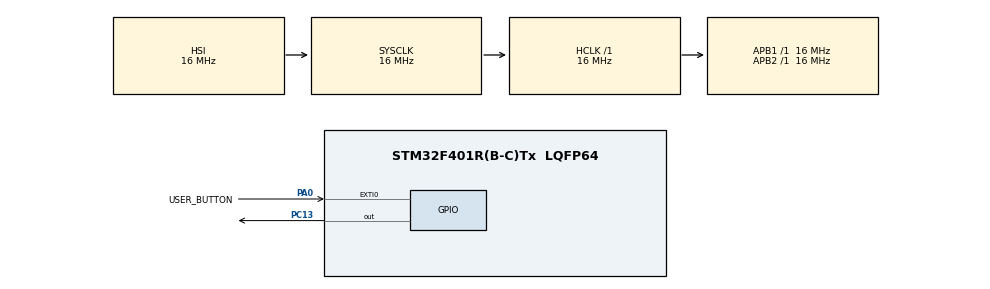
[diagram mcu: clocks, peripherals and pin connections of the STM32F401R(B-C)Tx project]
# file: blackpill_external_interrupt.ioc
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Mcu.Family=STM32F4
Mcu.Name=STM32F401R(B-C)Tx
Mcu.Package=LQFP64
NVIC.EXTI0_IRQn=true\:0\:0\:false\:false\:true\:true\:true\:true
NVIC.PriorityGroup=NVIC_PRIORITYGROUP_4
PA0-WKUP.GPIO_Label=USER_BUTTON
PA0-WKUP.GPIO_ModeDefaultEXTI=GPIO_MODE_IT_FALLING
PA0-WKUP.GPIO_PuPd=GPIO_PULLUP
PA0-WKUP.Signal=GPXTI0
PC13-ANTI_TAMP.PinState=GPIO_PIN_SET
PC13-ANTI_TAMP.Signal=GPIO_Output
ProjectManager.HeapSize=0x200
ProjectManager.StackSize=0x400
ProjectManager.TargetToolchain=STM32CubeIDE
RCC.AHBFreq_Value=16000000
RCC.APB1Freq_Value=16000000
RCC.APB2Freq_Value=16000000
RCC.CortexFreq_Value=16000000
RCC.HSE_VALUE=25000000
RCC.HSI_VALUE=16000000
RCC.LSE_VALUE=32768
RCC.SYSCLKFreq_VALUE=16000000
RCC.VCOOutputFreq_Value=192000000
board=custom

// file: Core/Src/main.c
/* USER CODE BEGIN Header */
/**
  ******************************************************************************
  * @file           : main.c
  * @brief          : Main program body
  ******************************************************************************
  * @attention
  *
  * Copyright (c) 2025 STMicroelectronics.
  * All rights reserved.
  *
  * This software is licensed under terms that can be found in the LICENSE file
  * in the root directory of this software component.
  * If no LICENSE file comes with this software, it is provided AS-IS.
  *
  ******************************************************************************
  */
/* USER CODE END Header */
#include "main.h"

void SystemClock_Config(void);
static void MX_GPIO_Init(void);

/* USER CODE BEGIN 0 */

uint8_t counter = 0; //Variable to select different toggling states

void HAL_GPIO_EXTI_Callback(uint16_t GPIO_Pin) //This function is called when an external interrupt occurs due to button press
{
	if(counter == 3) //Checking if max number of button presses have been reached and resetting if so
	{
		HAL_GPIO_WritePin(GPIOC, GPIO_PIN_13, 1); //It is essential to turn off the LED while resetting or else LED will stay on when the board resets while the LED was glowing in its previous state
		counter = 0; //Resetting the counter, LED will be OFF similar to when the board turns ON for the first time
	}
	else
	{
		++counter; //If max number of presses hasn't been reached, increment the counter
	}
}

/* USER CODE END 0 */

int main(void)
{

  /* MCU Configuration--------------------------------------------------------*/

  /* Reset of all peripherals, Initializes the Flash interface and the Systick. */
  HAL_Init();

  /* Configure the system clock */
  SystemClock_Config();

  /* Initialize all configured peripherals */
  MX_GPIO_Init();

  /* Infinite loop */
  while (1)
  {

    /* USER CODE BEGIN 3 */

	  if(counter == 1) //Toggling state 1 (fast switching)
	  {
		  HAL_GPIO_TogglePin(GPIOC, GPIO_PIN_13);
		  HAL_Delay(300);
	  }
	  else if(counter == 2) //Toggling state 2 (medium switching)
	  {
		  HAL_GPIO_TogglePin(GPIOC, GPIO_PIN_13);
		  HAL_Delay(900);
	  }
	  else if(counter == 3) //Toggling state 3 (slow switching)
	  {
		  HAL_GPIO_TogglePin(GPIOC, GPIO_PIN_13);
		  HAL_Delay(1500);
	  }

  }
  /* USER CODE END 3 */
}

void SystemClock_Config(void)
{
  RCC_OscInitTypeDef RCC_OscInitStruct = {0};
  RCC_ClkInitTypeDef RCC_ClkInitStruct = {0};

  /** Configure the main internal regulator output voltage
  */
  __HAL_RCC_PWR_CLK_ENABLE();
  __HAL_PWR_VOLTAGESCALING_CONFIG(PWR_REGULATOR_VOLTAGE_SCALE2);

  /** Initializes the RCC Oscillators according to the specified parameters
  * in the RCC_OscInitTypeDef structure.
  */
  RCC_OscInitStruct.OscillatorType = RCC_OSCILLATORTYPE_HSI;
  RCC_OscInitStruct.HSIState = RCC_HSI_ON;
  RCC_OscInitStruct.HSICalibrationValue = RCC_HSICALIBRATION_DEFAULT;
  RCC_OscInitStruct.PLL.PLLState = RCC_PLL_NONE;
  if (HAL_RCC_OscConfig(&RCC_OscInitStruct) != HAL_OK)
  {
    Error_Handler();
  }

  /** Initializes the CPU, AHB and APB buses clocks
  */
  RCC_ClkInitStruct.ClockType = RCC_CLOCKTYPE_HCLK|RCC_CLOCKTYPE_SYSCLK
                              |RCC_CLOCKTYPE_PCLK1|RCC_CLOCKTYPE_PCLK2;
  RCC_ClkInitStruct.SYSCLKSource = RCC_SYSCLKSOURCE_HSI;
  RCC_ClkInitStruct.AHBCLKDivider = RCC_SYSCLK_DIV1;
  RCC_ClkInitStruct.APB1CLKDivider = RCC_HCLK_DIV1;
  RCC_ClkInitStruct.APB2CLKDivider = RCC_HCLK_DIV1;

  if (HAL_RCC_ClockConfig(&RCC_ClkInitStruct, FLASH_LATENCY_0) != HAL_OK)
  {
    Error_Handler();
  }
}

static void MX_GPIO_Init(void)
{
  GPIO_InitTypeDef GPIO_InitStruct = {0};

  /* GPIO Ports Clock Enable */
  __HAL_RCC_GPIOC_CLK_ENABLE();
  __HAL_RCC_GPIOA_CLK_ENABLE();

  /*Configure GPIO pin Output Level */
  HAL_GPIO_WritePin(GPIOC, GPIO_PIN_13, GPIO_PIN_SET);

  /*Configure GPIO pin : PC13 */
  GPIO_InitStruct.Pin = GPIO_PIN_13;
  GPIO_InitStruct.Mode = GPIO_MODE_OUTPUT_PP;
  GPIO_InitStruct.Pull = GPIO_NOPULL;
  GPIO_InitStruct.Speed = GPIO_SPEED_FREQ_LOW;
  HAL_GPIO_Init(GPIOC, &GPIO_InitStruct);

  /*Configure GPIO pin : USER_BUTTON_Pin */
  GPIO_InitStruct.Pin = USER_BUTTON_Pin;
  GPIO_InitStruct.Mode = GPIO_MODE_IT_FALLING;
  GPIO_InitStruct.Pull = GPIO_PULLUP;
  HAL_GPIO_Init(USER_BUTTON_GPIO_Port, &GPIO_InitStruct);

  /* EXTI interrupt init*/
  HAL_NVIC_SetPriority(EXTI0_IRQn, 0, 0);
  HAL_NVIC_EnableIRQ(EXTI0_IRQn);

}

void Error_Handler(void)
{
  __disable_irq();
  while (1)
  {
  }
}
